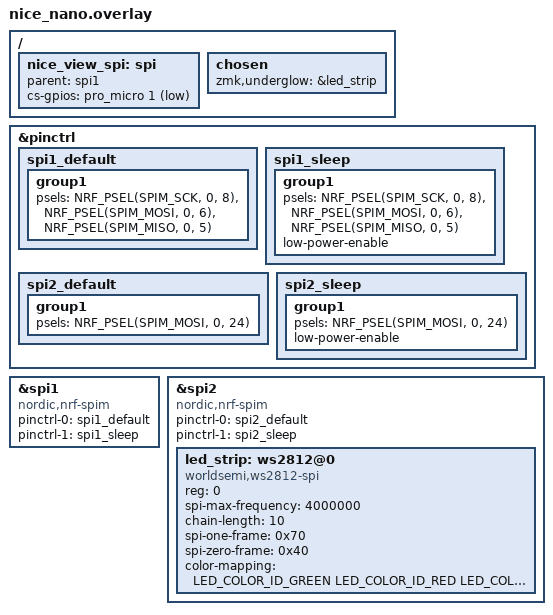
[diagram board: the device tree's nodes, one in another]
#include <dt-bindings/led/led.h>
#include <dt-bindings/pinctrl/nrf-pinctrl.h>
#include <dt-bindings/gpio/gpio.h>

// Configure SPI1 for nice_view display
&pinctrl {
    spi1_default: spi1_default {
        group1 {
            psels = <NRF_PSEL(SPIM_SCK, 0, 8)>,
                    <NRF_PSEL(SPIM_MOSI, 0, 6)>,
                    <NRF_PSEL(SPIM_MISO, 0, 5)>;
        };
    };
    
    spi1_sleep: spi1_sleep {
        group1 {
            psels = <NRF_PSEL(SPIM_SCK, 0, 8)>,
                    <NRF_PSEL(SPIM_MOSI, 0, 6)>,
                    <NRF_PSEL(SPIM_MISO, 0, 5)>;
            low-power-enable;
        };
    };
    
    spi2_default: spi2_default {
        group1 {
            psels = <NRF_PSEL(SPIM_MOSI, 0, 24)>;
        };
    };

    spi2_sleep: spi2_sleep {
        group1 {
            psels = <NRF_PSEL(SPIM_MOSI, 0, 24)>;
            low-power-enable;
        };
    };
};

&spi1 {
    compatible = "nordic,nrf-spim";
    status = "okay";
    pinctrl-0 = <&spi1_default>;
    pinctrl-1 = <&spi1_sleep>;
    pinctrl-names = "default", "sleep";
};

&spi2 {
    compatible = "nordic,nrf-spim";
    status = "okay";

    pinctrl-0 = <&spi2_default>;
    pinctrl-1 = <&spi2_sleep>;
    pinctrl-names = "default", "sleep";

    led_strip: ws2812@0 {
        compatible = "worldsemi,ws2812-spi";

        reg = <0>;
        spi-max-frequency = <4000000>;

        chain-length = <10>;
        spi-one-frame = <0x70>;
        spi-zero-frame = <0x40>;
        color-mapping = <LED_COLOR_ID_GREEN LED_COLOR_ID_RED LED_COLOR_ID_BLUE>;
    };
};

/ {
    nice_view_spi: spi {
        parent = <&spi1>;
        status = "okay";
        cs-gpios = <&pro_micro 1 GPIO_ACTIVE_LOW>;
    };

    chosen {
        zmk,underglow = &led_strip;
    };
};
